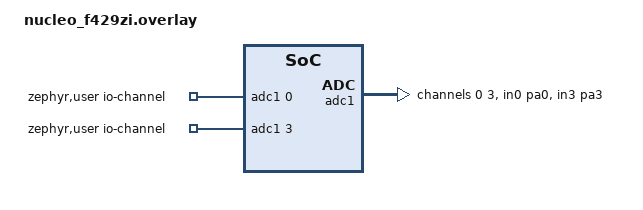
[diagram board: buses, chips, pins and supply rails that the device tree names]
/*
 * SPDX-License-Identifier: Apache-2.0
 *
 * Copyright (c) Benjamin Björnsson <benjamin.bjornsson@gmail.com>
 */

/ {
	zephyr,user {
		/* adjust channel number according to pinmux in board.dts */
		io-channels = <&adc1 0>, <&adc1 3>;
	};
};

&adc1 {
	pinctrl-0 = <&adc1_in0_pa0 &adc1_in3_pa3>;
	#address-cells = <1>;
	#size-cells = <0>;

	channel@0 {
		reg = <0>;
		zephyr,gain = "ADC_GAIN_1";
		zephyr,reference = "ADC_REF_INTERNAL";
		zephyr,acquisition-time = <ADC_ACQ_TIME_MAX>;
		zephyr,resolution = <12>;
	};

	channel@3 {
		reg = <3>;
		zephyr,gain = "ADC_GAIN_1";
		zephyr,reference = "ADC_REF_INTERNAL";
		zephyr,acquisition-time = <ADC_ACQ_TIME_MAX>;
		zephyr,resolution = <12>;
	};
};
